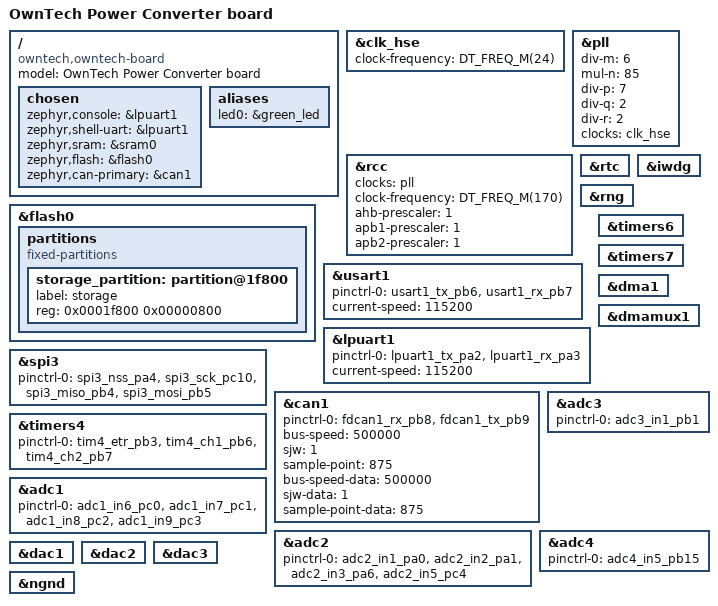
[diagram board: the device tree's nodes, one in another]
/*
 * Copyright (c) 2022 OwnTech.
 *
 * SPDX-License-Identifier: LGLPV2.1
 */

/dts-v1/;

// SOC defintions
#include <st/g4/stm32g474Xe.dtsi>
#include <st/g4/stm32g474r(b-c-e)tx-pinctrl.dtsi>

// Board-related definitions
#include "dts/pinctrl.dtsi"
#include "dts/led.dtsi"
#include "dts/hrtim.dtsi"
#include "dts/adc.dtsi"
#include "dts/adc-channels.dtsi"
#include "dts/ngnd.dtsi"
#include "dts/can-standby-switch.dtsi"
#include "dts/gpio.dtsi"


/ {
	model = "OwnTech Power Converter board";
	compatible = "owntech,owntech-board", "st,stm32g474re-nucleo";

	chosen {
		zephyr,console = &lpuart1;
		zephyr,shell-uart = &lpuart1;
		zephyr,sram = &sram0;
		zephyr,flash = &flash0;
		zephyr,can-primary = &can1;
	};

	aliases {
		led0 = &green_led;
	};
};

&clk_hse {
	clock-frequency = <DT_FREQ_M(24)>;
	status = "okay";
};

&pll {
	div-m = <6>;
	mul-n = <85>;
	div-p = <7>;
	div-q = <2>;
	div-r = <2>;
	clocks = <&clk_hse>;
	status = "okay";
};

&rcc {
	clocks = <&pll>;
	clock-frequency = <DT_FREQ_M(170)>;
	ahb-prescaler = <1>;
	apb1-prescaler = <1>;
	apb2-prescaler = <1>;
};

&rtc {
	status = "okay";
};

&flash0 {
	/*
	 * For more information, see:
	 * http://docs.zephyrproject.org/latest/guides/dts/index.html#flash-partitions
	 */
	partitions {
		compatible = "fixed-partitions";
		#address-cells = <1>;
		#size-cells = <1>;

		/* Set 2Kb of storage at the end of the 128Kb of flash */
		storage_partition: partition@1f800 {
			label = "storage";
			reg = <0x0001f800 0x00000800>;
		};
	};
};

&iwdg {
	status = "okay";
};

&rng {
	status = "okay";
};

/*****************/
/* Communication */
/*****************/

// UART

&usart1 {
	pinctrl-0 = <&usart1_tx_pb6 &usart1_rx_pb7>;
	current-speed = <115200>;
	status = "okay";
};

&lpuart1 {
	pinctrl-0 = <&lpuart1_tx_pa2 &lpuart1_rx_pa3>;
	current-speed = <115200>;
	status = "okay";
};

// SPI

&spi3 {
	pinctrl-0 = <&spi3_nss_pa4 &spi3_sck_pc10 &spi3_miso_pb4 &spi3_mosi_pb5>;
	status = "okay";
};

// CAN

&can1 {
	pinctrl-0 = <&fdcan1_rx_pb8 &fdcan1_tx_pb9>;
	bus-speed = <500000>;
	sjw = <1>;
	sample-point = <875>;
	bus-speed-data = <500000>;
	sjw-data = <1>;
	sample-point-data = <875>;
	status = "okay";
};

/*********/
/* Timer */
/*********/

&timers4 {
	pinctrl-names = "incremental_encoder";
	pinctrl-0 = <&tim4_etr_pb3 &tim4_ch1_pb6 &tim4_ch2_pb7 >;
	status = "okay";
};

&timers6 {
	status = "okay";
};

&timers7 {
	status = "okay";
};

/*******/
/* DMA */
/*******/

&dma1 {
	status = "okay";
};

&dmamux1 {
	status = "okay";
};

/*******/
/* ADC */
/*******/

&adc1 {
	pinctrl-0 = <&adc1_in6_pc0 &adc1_in7_pc1 &adc1_in8_pc2 &adc1_in9_pc3>;
	status = "okay";
};

&adc2 {
	pinctrl-0 = <&adc2_in1_pa0 &adc2_in2_pa1 &adc2_in3_pa6 &adc2_in5_pc4>;
	status = "okay";
};

&adc3 {
	pinctrl-0 = <&adc3_in1_pb1 >;
	status = "okay";
};

&adc4 {
	pinctrl-0 = <&adc4_in5_pb15 >;
	status = "okay";
};

/*******/
/* DAC */
/*******/

&dac1 {
	status = "okay";
};

&dac2 {
	status = "okay";
};

&dac3 {
	status = "okay";
};

/********/
/* NGND */
/********/

&ngnd {
	status = "okay";
};
